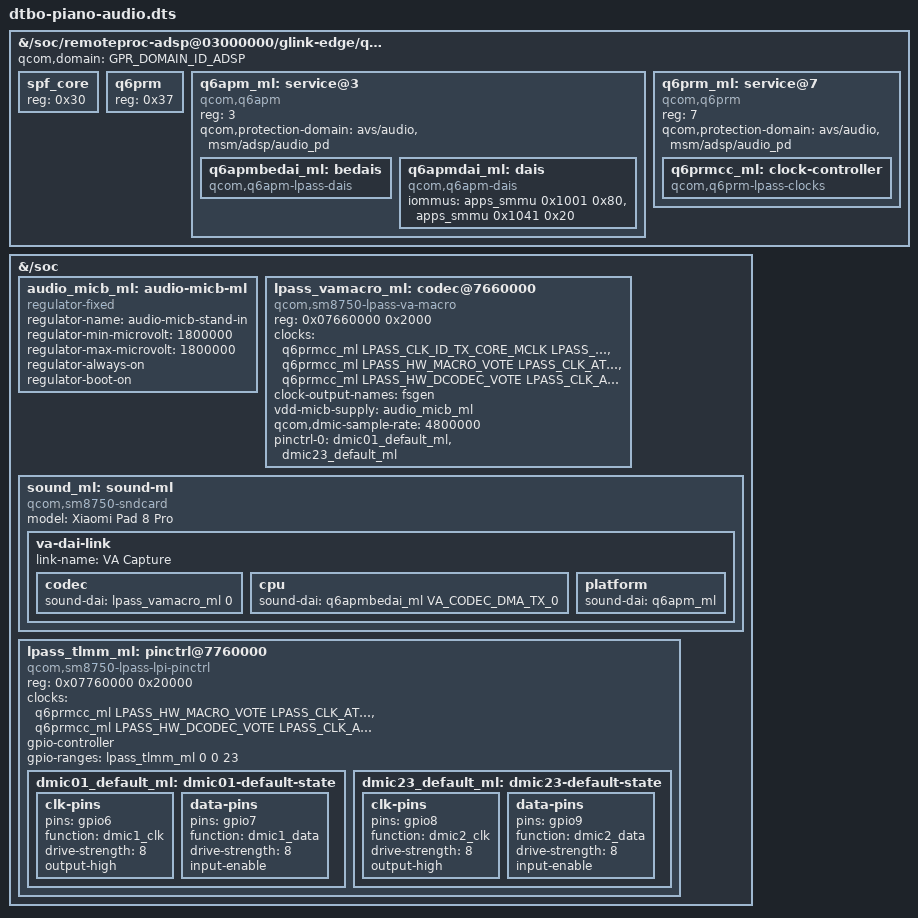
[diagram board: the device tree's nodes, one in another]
// SPDX-License-Identifier: GPL-2.0-only
/* Audio profile: the AudioReach chain on the ADSP with the digital
 * microphones (VA macro, codec-DMA capture).
 *
 * Register layout, clocks and bindings follow upstream sm8750.dtsi,
 * converted to the 1-cell /soc bus of the stock base; every node is added
 * next to the stock downstream audio nodes, which stay driverless.  The
 * stock gpr node keeps its downstream children (spf_core, q6prm,
 * audio-pkt: no driver) and gains the mainline domain id and services.
 *
 * Not here (yet): the WCD9395 headset codec and the four Foursemi
 * FS19xx speaker amplifiers.  The speakers sit on the secondary TDM port
 * (stock resourcemanager: TDM-LPAIF-RX-SECONDARY), which the mainline
 * AudioReach stack does not implement.
 *
 * The microphone bias supply is a fixed stand-in: nothing here writes an
 * RPMh rail.
 */
#include "dtbo-piano-subsys.dts"
#include <dt-bindings/gpio/gpio.h>
#include <dt-bindings/sound/qcom,q6dsp-lpass-ports.h>
#include <dt-bindings/soc/qcom,gpr.h>

/ {
	/*
	 * The SM8750 ADSP firmware only answers the static GPR source ports of
	 * the downstream service ids: the APM client is 3 (stock spf_core) and
	 * the PRM client 7 (stock q6prm); mainline's 1 and 2 are dropped
	 * silently.  Move the stock driverless children out of the way and
	 * take their ids.  (q6apm follows its reg as source port, see
	 * audioreach_set_apm_src_port().)
	 */
	fragment@300 {
		target-path = "/soc/remoteproc-adsp@03000000/glink-edge/qcom,gpr";
		__overlay__ {
			qcom,domain = <GPR_DOMAIN_ID_ADSP>;
			#address-cells = <1>;
			#size-cells = <0>;

			spf_core {
				reg = <0x30>;
			};

			q6prm {
				reg = <0x37>;
			};

			q6apm_ml: service@3 {
				compatible = "qcom,q6apm";
				reg = <3>;
				#sound-dai-cells = <0>;
				qcom,protection-domain = "avs/audio", "msm/adsp/audio_pd";

				q6apmbedai_ml: bedais {
					compatible = "qcom,q6apm-lpass-dais";
					#sound-dai-cells = <1>;
				};

				/*
				 * The ADSP takes the stream id of its accesses to
				 * PCM buffers from address bits 32+, which
				 * q6apm-dai fills from the first iommus entry.
				 * Without it the ADSP uses 0x1000, a stream with
				 * no match, and the first capture resets the SoC.
				 * The stock SMMU node has no driver, so the
				 * buffers stay untranslated like fastrpc's, on
				 * the 0x1001/0x80 and 0x1041/0x20 bypass matches
				 * that rootfs-init writes.
				 */
				q6apmdai_ml: dais {
					compatible = "qcom,q6apm-dais";
					iommus = <&apps_smmu 0x1001 0x80>,
						 <&apps_smmu 0x1041 0x20>;
				};
			};

			q6prm_ml: service@7 {
				compatible = "qcom,q6prm";
				reg = <7>;
				qcom,protection-domain = "avs/audio", "msm/adsp/audio_pd";

				q6prmcc_ml: clock-controller {
					compatible = "qcom,q6prm-lpass-clocks";
					#clock-cells = <2>;
				};
			};
		};
	};

	fragment@301 {
		target-path = "/soc";
		__overlay__ {
			audio_micb_ml: audio-micb-ml {
				compatible = "regulator-fixed";
				regulator-name = "audio-micb-stand-in";
				regulator-min-microvolt = <1800000>;
				regulator-max-microvolt = <1800000>;
				regulator-always-on;
				regulator-boot-on;
			};

			lpass_vamacro_ml: codec@7660000 {
				compatible = "qcom,sm8750-lpass-va-macro", "qcom,sm8550-lpass-va-macro";
				reg = <0x07660000 0x2000>;
				clocks = <&q6prmcc_ml LPASS_CLK_ID_TX_CORE_MCLK LPASS_CLK_ATTRIBUTE_COUPLE_NO>,
					 <&q6prmcc_ml LPASS_HW_MACRO_VOTE LPASS_CLK_ATTRIBUTE_COUPLE_NO>,
					 <&q6prmcc_ml LPASS_HW_DCODEC_VOTE LPASS_CLK_ATTRIBUTE_COUPLE_NO>;
				clock-names = "mclk", "macro", "dcodec";
				#clock-cells = <0>;
				clock-output-names = "fsgen";
				#sound-dai-cells = <1>;
				vdd-micb-supply = <&audio_micb_ml>;
				qcom,dmic-sample-rate = <4800000>;
				pinctrl-names = "default";
				pinctrl-0 = <&dmic01_default_ml>, <&dmic23_default_ml>;
			};

			sound_ml: sound-ml {
				compatible = "qcom,sm8750-sndcard", "qcom,sm8450-sndcard";
				model = "Xiaomi Pad 8 Pro";

				va-dai-link {
					link-name = "VA Capture";

					codec {
						sound-dai = <&lpass_vamacro_ml 0>;
					};

					cpu {
						sound-dai = <&q6apmbedai_ml VA_CODEC_DMA_TX_0>;
					};

					platform {
						sound-dai = <&q6apm_ml>;
					};
				};
			};

			lpass_tlmm_ml: pinctrl@7760000 {
				compatible = "qcom,sm8750-lpass-lpi-pinctrl",
					     "qcom,sm8650-lpass-lpi-pinctrl";
				reg = <0x07760000 0x20000>;
				clocks = <&q6prmcc_ml LPASS_HW_MACRO_VOTE LPASS_CLK_ATTRIBUTE_COUPLE_NO>,
					 <&q6prmcc_ml LPASS_HW_DCODEC_VOTE LPASS_CLK_ATTRIBUTE_COUPLE_NO>;
				clock-names = "core", "audio";
				gpio-controller;
				#gpio-cells = <2>;
				gpio-ranges = <&lpass_tlmm_ml 0 0 23>;

				dmic01_default_ml: dmic01-default-state {
					clk-pins {
						pins = "gpio6";
						function = "dmic1_clk";
						drive-strength = <8>;
						output-high;
					};

					data-pins {
						pins = "gpio7";
						function = "dmic1_data";
						drive-strength = <8>;
						input-enable;
					};
				};

				dmic23_default_ml: dmic23-default-state {
					clk-pins {
						pins = "gpio8";
						function = "dmic2_clk";
						drive-strength = <8>;
						output-high;
					};

					data-pins {
						pins = "gpio9";
						function = "dmic2_data";
						drive-strength = <8>;
						input-enable;
					};
				};
			};
		};
	};
};
